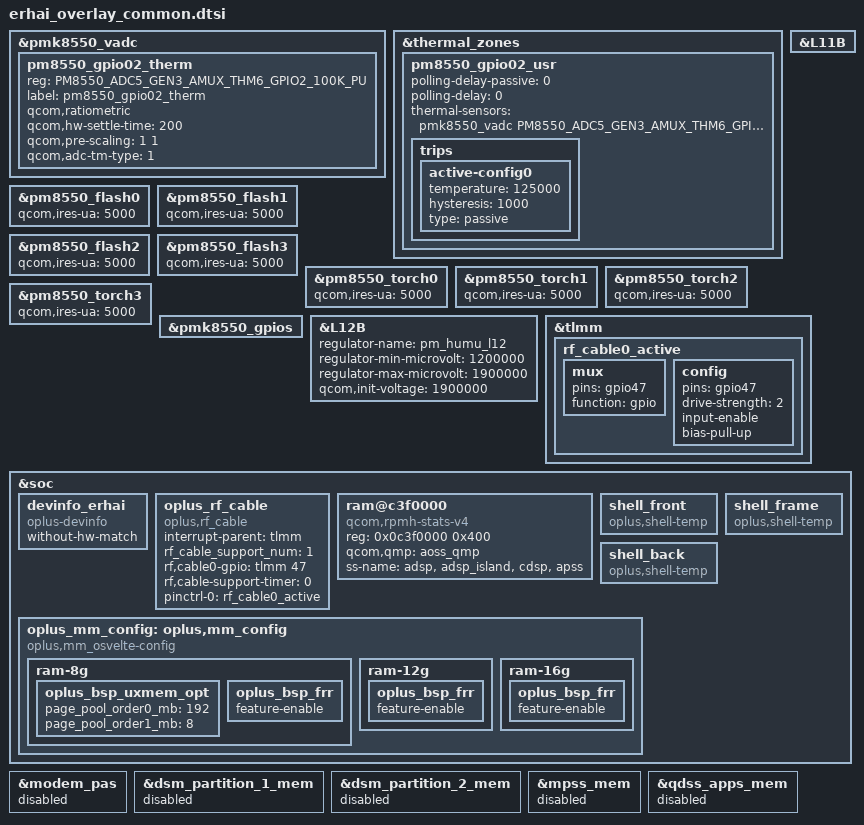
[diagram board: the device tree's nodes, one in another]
&pmk8550_vadc {
	pm8550_gpio02_therm {
		reg = <PM8550_ADC5_GEN3_AMUX_THM6_GPIO2_100K_PU>;
		label = "pm8550_gpio02_therm";
		qcom,ratiometric;
		qcom,hw-settle-time = <200>;
		qcom,pre-scaling = <1 1>;
		qcom,adc-tm-type = <1>;
	};

};

&thermal_zones {
	pm8550_gpio02_usr {
		polling-delay-passive = <0>;
		polling-delay = <0>;
		thermal-sensors = <&pmk8550_vadc PM8550_ADC5_GEN3_AMUX_THM6_GPIO2_100K_PU>;
		trips {
			active-config0 {
				temperature = <125000>;
				hysteresis = <1000>;
				type = "passive";
			};
		};
	};

};
&pm8550_flash0 {
	qcom,ires-ua = <5000>;
};

&pm8550_flash1 {
	qcom,ires-ua = <5000>;
};

&pm8550_flash2 {
	qcom,ires-ua = <5000>;
};

&pm8550_flash3 {
	qcom,ires-ua = <5000>;
};

&pm8550_torch0 {
	qcom,ires-ua = <5000>;
};

&pm8550_torch1 {
	qcom,ires-ua = <5000>;
};

&pm8550_torch2 {
	qcom,ires-ua = <5000>;
};

&pm8550_torch3 {
	qcom,ires-ua = <5000>;
};

&L11B {
	/delete-property/ qcom,proxy-consumer-enable;
};

&pmk8550_gpios {
	/delete-property/ pinctrl-0;
	/delete-property/ pinctrl-names;
	/delete-node/ alt_sleep_clk;
};

&L12B {
	regulator-name = "pm_humu_l12";
	regulator-min-microvolt = <1200000>;
	regulator-max-microvolt = <1900000>;
	qcom,init-voltage = <1900000>;
	/delete-property/ qcom,proxy-consumer-enable;
};

&tlmm {
	//#ifdef OPLUS_FEATURE_RF_CABLE_DETECT
	rf_cable0_active: rf_cable0_active {
		mux {
			pins = "gpio47";
			function = "gpio";
		};
		config {
			pins = "gpio47";
			drive-strength = <2>;
			input-enable;
			bias-pull-up;
		};
	};
	//#endif /* OPLUS_FEATURE_RF_CABLE_DETECT */
};

&soc {
	devinfo_erhai {
		compatible = "oplus-devinfo";
		without-hw-match;
	};
};

&soc {
	//#ifdef OPLUS_FEATURE_RF_CABLE_DETECT
	oplus_rf_cable {
		compatible = "oplus,rf_cable";
		interrupt-parent = <&tlmm>;
		rf_cable_support_num = <1>;
		rf,cable0-gpio = <&tlmm 47 0>;
		rf,cable-support-timer = <0>;
		pinctrl-names = "rf_cable_active";
		pinctrl-0 = <&rf_cable0_active>;
	};
	//#endif /* OPLUS_FEATURE_RF_CABLE_DETECT */

	ram@c3f0000 {
		compatible = "qcom,rpmh-stats-v4";
		reg = <0x0c3f0000 0x400>;
		qcom,qmp = <&aoss_qmp>;
		ss-name = "adsp", "adsp_island",
			  "cdsp", "apss";
		};

	//#ifdef OPLUS_FEATURE_THERMAL_HORAE
	shell_front {
		compatible = "oplus,shell-temp";
	};

	shell_frame {
		compatible = "oplus,shell-temp";
	};

	shell_back {
		compatible = "oplus,shell-temp";
	};
	//#endif /* OPLUS_FEATURE_THERMAL_HORAE */
};

&modem_pas {
    status = "no";
};
&dsm_partition_1_mem {
    status = "disabled";
};
&dsm_partition_2_mem{
    status = "disabled";
};
&mpss_mem{
    status = "disabled";
};
&qdss_apps_mem {
    status = "disabled";
};

&soc {
	oplus_mm_config: oplus,mm_config {
		compatible = "oplus,mm_osvelte-config";
		ram-8g {
			oplus_bsp_uxmem_opt {
				page_pool_order0_mb = <192>;
				page_pool_order1_mb = <8>;
			};
			oplus_bsp_frr {
				 feature-enable;
			};
		};
		ram-12g {
			 oplus_bsp_frr {
				feature-enable;
			};
		};
		ram-16g {
			oplus_bsp_frr {
				feature-enable;
			};
		};
	};
};

